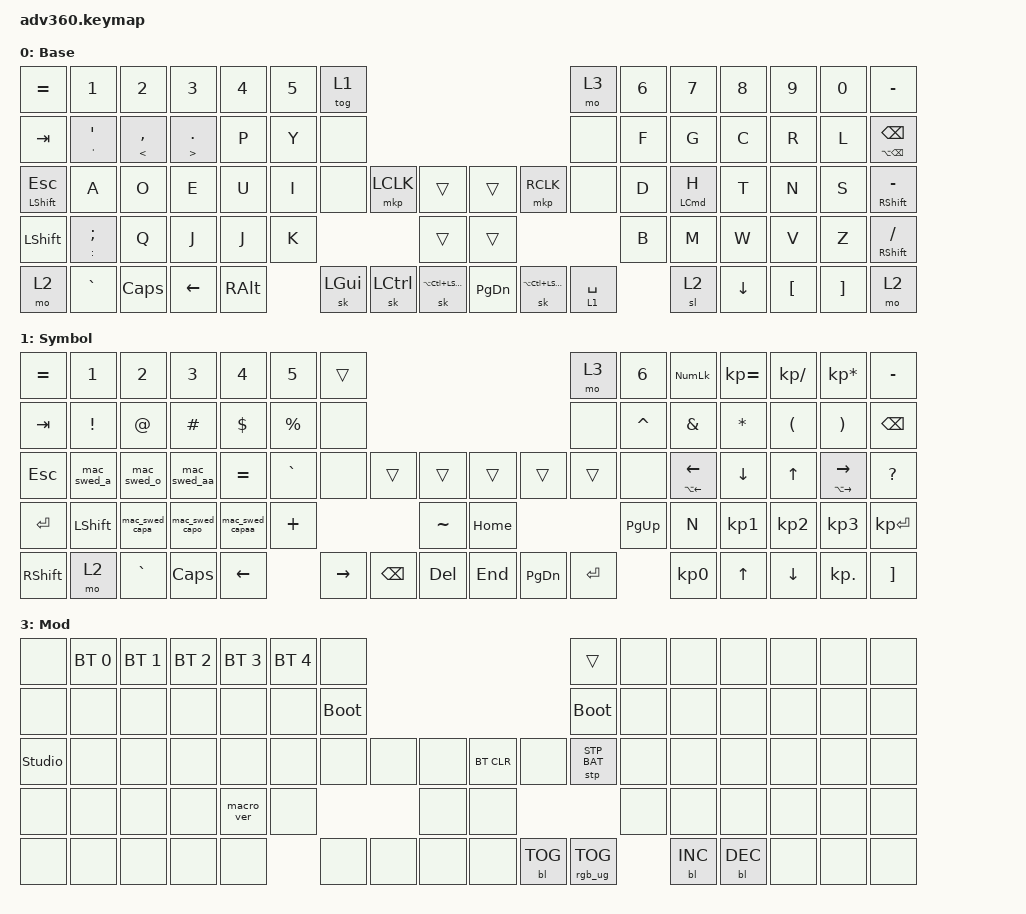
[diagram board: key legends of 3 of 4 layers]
#include <dt-bindings/zmk/stp.h>
#include <behaviors.dtsi>
#include <dt-bindings/zmk/backlight.h>
#include <dt-bindings/zmk/bt.h>
#include <dt-bindings/zmk/keys.h>
#include <dt-bindings/zmk/pointing.h>
#include <dt-bindings/zmk/rgb.h>

/ {
    behaviors {
        #include "macros.dtsi"
      #include "version.dtsi"

        hm: homerow_mods {
            compatible = "zmk,behavior-hold-tap";
            label = "HOMEROW_MODS";
            #binding-cells = <2>;
            tapping-term-ms = <200>;
            quick_tap_ms = <175>;
            flavor = "tap-preferred";
            bindings = <&kp>, <&kp>;
        };

        hold_tap: hold_tap {
            compatible = "zmk,behavior-hold-tap";
            label = "HOLD_TAP";
            bindings = <&kp>, <&kp>;

            #binding-cells = <2>;
            tapping-term-ms = <200>;
            quick-tap-ms = <0>;
            flavor = "tap-preferred";
        };
    };

    macros {
        mac_swed_a: mac_swed_a {
            label = "mac_swed_a";
            compatible = "zmk,behavior-macro";
            #binding-cells = <0>;
            bindings = <&macro_tap>, <&kp RA(A)>;
        };

        mac_swed_o: mac_swed_o {
            label = "mac_swed_o";
            compatible = "zmk,behavior-macro";
            #binding-cells = <0>;
            bindings = <&macro_tap>, <&kp RA(U) &kp O>;
        };

        mac_swed_aa: mac_swed_aa {
            label = "mac_swed_aa";
            compatible = "zmk,behavior-macro";
            #binding-cells = <0>;
            bindings = <&macro_tap>, <&kp RA(U) &kp A>;
        };

        mac_swed_capa: mac_swed_capa {
            label = "mac_swed_capa";
            compatible = "zmk,behavior-macro";
            #binding-cells = <0>;
            bindings = <&macro_tap>, <&kp LS(RA(A))>;
        };

        mac_swed_capo: mac_swed_capo {
            label = "mac_swed_capo";
            compatible = "zmk,behavior-macro";
            #binding-cells = <0>;
            bindings = <&macro_tap>, <&kp RA(U) &kp LS(O)>;
        };

        mac_swed_capaa: mac_swed_capaa {
            label = "mac_swed_capaa";
            compatible = "zmk,behavior-macro";
            #binding-cells = <0>;
            bindings = <&macro_tap>, <&kp RA(U) &kp LS(A)>;
        };
    };

    keymap {
        compatible = "zmk,keymap";

        default_layer {
            display-name = "Base";
            bindings = <
&kp EQUAL                    &kp N1                         &kp N2               &kp N3                   &kp N4    &kp N5  &tog 1                                                                                  &mo 3        &kp N6  &kp N7                    &kp N8    &kp N9    &kp N0    &kp MINUS
&kp TAB                      &mt SINGLE_QUOTE SINGLE_QUOTE  &mt LESS_THAN COMMA  &mt GREATER_THAN PERIOD  &kp P     &kp Y   &none                                                                                   &none        &kp F   &kp G                     &kp C     &kp R     &kp L     &mt LA(BACKSPACE) BACKSPACE
&hold_tap LEFT_SHIFT ESCAPE  &kp A                          &kp O                &kp E                    &kp U     &kp I   &none         &mkp LCLK  &trans                      &trans     &mkp RCLK               &none        &kp D   &hold_tap LEFT_COMMAND H  &kp T     &kp N     &kp S     &hold_tap RIGHT_SHIFT MINUS
&kp LSHFT                    &mt COLON SEMICOLON            &kp Q                &kp J                    &kp J     &kp K                            &trans                      &trans                                          &kp B   &kp M                     &kp W     &kp V     &kp Z     &hold_tap RIGHT_SHIFT SLASH
&mo 2                        &kp GRAVE                      &kp CAPS             &kp LEFT                 &kp RALT          &sk LEFT_GUI  &sk LCTRL  &sk LA(LC(LEFT_SHIFT))      &kp PG_DN  &sk LA(LC(LEFT_SHIFT))  &lt 1 SPACE          &sl 2                     &kp DOWN  &kp LBKT  &kp RBKT  &mo 2
            >;
        };

        keypad {
            display-name = "Symbol";
            bindings = <
&kp EQUAL  &kp N1           &kp N2          &kp N3          &kp N4           &kp N5       &trans                                                   &mo 3      &kp N6     &kp KP_NUM                     &kp KP_EQUAL    &kp KP_DIVIDE  &kp KP_MULTIPLY                  &kp MINUS
&kp TAB    &kp EXCLAMATION  &kp AT          &kp HASH        &kp DOLLAR       &kp PERCENT  &none                                                    &none      &kp CARET  &kp AMPS                       &kp ASTERISK    &kp LPAR       &kp RPAR                         &kp BACKSPACE
&kp ESC    &mac_swed_a      &mac_swed_o     &mac_swed_aa    &kp EQUAL        &kp GRAVE    &none      &trans    &trans         &trans    &trans     &trans     &none      &mt LA(LEFT_ARROW) LEFT_ARROW  &kp DOWN_ARROW  &kp UP_ARROW   &mt LA(RIGHT_ARROW) RIGHT_ARROW  &kp QUESTION
&kp ENTER  &kp LSHFT        &mac_swed_capa  &mac_swed_capo  &mac_swed_capaa  &kp PLUS                          &kp TILDE      &kp HOME                        &kp PG_UP  &kp N                          &kp KP_N1       &kp KP_N2      &kp KP_N3                        &kp KP_ENTER
&kp RSHFT  &mo 2            &kp GRAVE       &kp CAPS        &kp LEFT                      &kp RIGHT  &kp BSPC  &kp DEL        &kp END   &kp PG_DN  &kp ENTER             &kp KP_N0                      &kp UP          &kp DOWN       &kp KP_DOT                       &kp RBKT
            >;
        };

        fn {
            display-name = "Number";
            bindings = <
&kp F1  &kp F2  &kp F3  &kp F4  &kp F5  &kp F6  &tog 1                                      &mo 3   &kp F7        &kp F8        &kp F9        &kp F10       &kp F11  &kp F12
&trans  &trans  &trans  &trans  &trans  &trans  &none                                       &none   &kp NUMBER_6  &kp N7        &kp N8        &kp N9        &kp N0   &trans
&trans  &trans  &trans  &trans  &trans  &none   &trans  &trans  &trans      &trans  &trans  &none   &kp NUMBER_1  &kp NUMBER_2  &kp NUMBER_3  &kp NUMBER_4  &kp N5   &trans
&trans  &trans  &trans  &trans  &trans  &trans                  &trans      &trans                  &trans        &trans        &trans        &trans        &trans   &trans
&trans  &trans  &trans  &trans  &trans          &trans  &trans  &trans      &trans  &trans  &trans                &trans        &trans        &trans        &trans
            >;
        };

        mod {
            display-name = "Mod";
            bindings = <
&none           &bt BT_SEL 0  &bt BT_SEL 1  &bt BT_SEL 2  &bt BT_SEL 3  &bt BT_SEL 4  &none                                                  &trans           &none  &none       &none       &none  &none  &none
&none           &none         &none         &none         &none         &none         &bootloader                                            &bootloader      &none  &none       &none       &none  &none  &none
&studio_unlock  &none         &none         &none         &none         &none         &none        &none  &none      &bt BT_CLR  &none       &stp STP_BAT     &none  &none       &none       &none  &none  &none
&none           &none         &none         &none         &macro_ver    &none                             &none      &none                                    &none  &none       &none       &none  &none  &none
&none           &none         &none         &none         &none                       &none        &none  &none      &none       &bl BL_TOG  &rgb_ug RGB_TOG         &bl BL_INC  &bl BL_DEC  &none  &none  &none
            >;
        };

        extra1 {
            display-name = "Red";
            status = "reserved";
        };

        extra2 {
            display-name = "Purple";
            status = "reserved";
        };

        extra3 {
            display-name = "Cyan";
            status = "reserved";
        };

        extra4 {
            display-name = "Yellow";
            status = "reserved";
        };
    };
};
